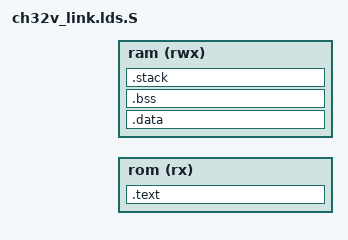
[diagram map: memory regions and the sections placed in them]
// Linker script for WCH CH32V (QingKe RISC-V)
//
// Copyright (C) 2026
//
// This file may be distributed under the terms of the GNU GPLv3 license.

#include "autoconf.h" // CONFIG_FLASH_APPLICATION_ADDRESS, CONFIG_RAM_*

OUTPUT_FORMAT("elf32-littleriscv", "elf32-littleriscv", "elf32-littleriscv")
OUTPUT_ARCH(riscv)

MEMORY
{
  rom (rx) : ORIGIN = CONFIG_FLASH_APPLICATION_ADDRESS , LENGTH = CONFIG_FLASH_SIZE
  ram (rwx) : ORIGIN = CONFIG_RAM_START , LENGTH = CONFIG_RAM_SIZE
}

SECTIONS
{
    .text : {
        . = ALIGN(4);
        _text_vectortable_start = .;
        KEEP(*(.vector_table))
        _text_vectortable_end = .;
        *(.text .text.*)
        *(.rodata .rodata*)
        . = ALIGN(4);
    } > rom

    . = ALIGN(4);
    _data_flash = .;

    .data : AT (_data_flash)
    {
        . = ALIGN(4);
        _data_start = .;
        *(.ramfunc .ramfunc.*);
        *(.data .data.*);
        *(.sdata .sdata.*);
        . = ALIGN(4);
        _data_end = .;
    } > ram

    .bss (NOLOAD) :
    {
        . = ALIGN(4);
        _bss_start = .;
        *(.sbss .sbss.*)
        *(.bss .bss.*)
        *(COMMON)
        . = ALIGN(4);
        _bss_end = .;
    } > ram

    _stack_start = CONFIG_RAM_START + CONFIG_RAM_SIZE - CONFIG_STACK_SIZE ;
    .stack _stack_start (NOLOAD) :
    {
        . = . + CONFIG_STACK_SIZE;
        _stack_end = .;
    } > ram

    /DISCARD/ : {
        *(.init)
        *(.fini)
        *(.riscv.attributes)
        *(.comment)
    }
}
